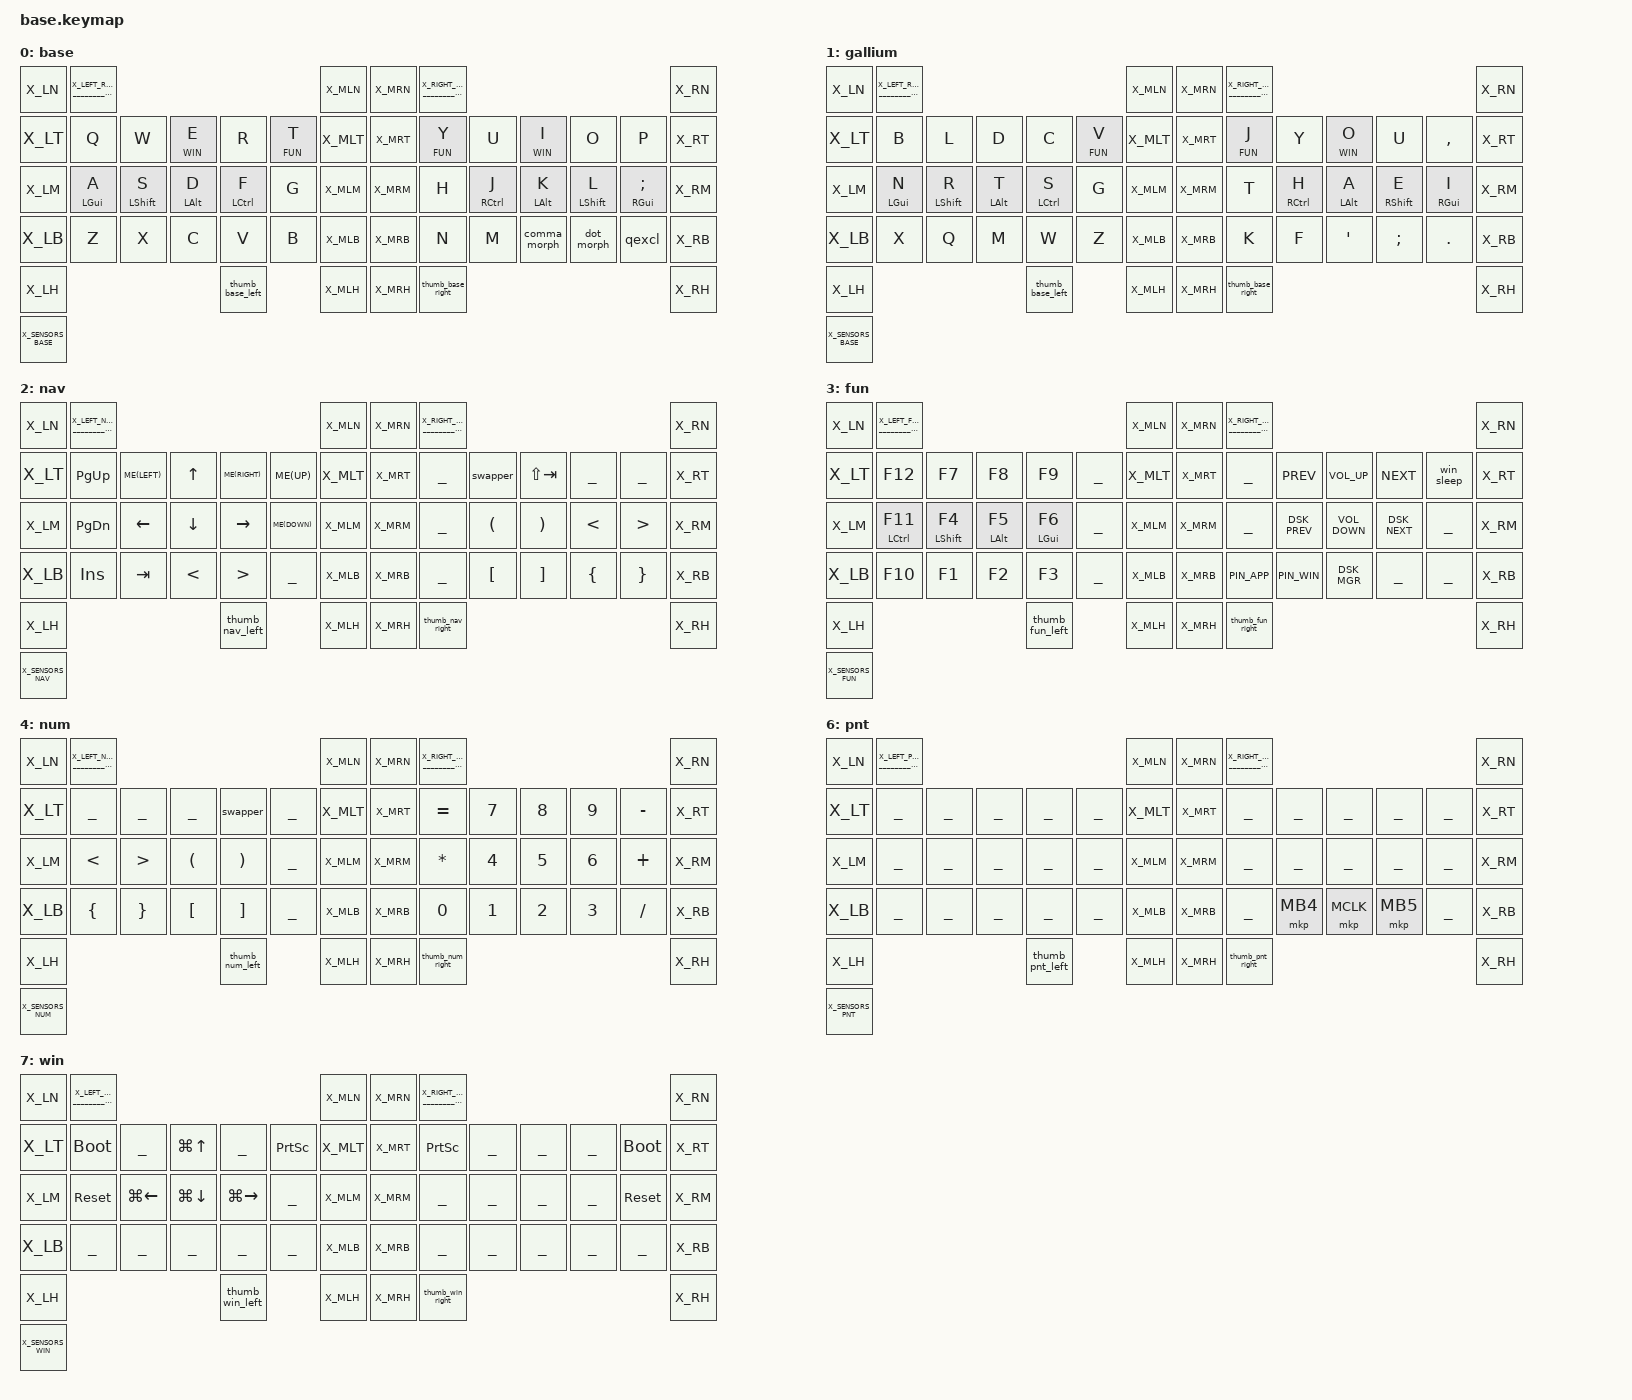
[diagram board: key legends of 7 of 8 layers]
#include <behaviors.dtsi>
#include <dt-bindings/zmk/keys.h>

#include "zmk-helpers/helper.h"

#include "../spacerock/aliases.h"
#include "../spacerock/extra_keys.h"
#include "../spacerock/layouts.h"

#include "../spacerock/hardware/hardware.dtsi"
#include "../spacerock/behaviors/behaviors.dtsi"
#include "../spacerock/behaviors/leader.dtsi"

#include "../spacerock/features/hrm.dtsi"
#include "../spacerock/features/mask_mods.dtsi"
#include "../spacerock/features/caps_word.dtsi"
#include "../spacerock/features/num_word.dtsi"
#include "../spacerock/features/smart_mouse.dtsi"
#include "../spacerock/features/swapper.dtsi"
#include "../spacerock/features/smart_shift.dtsi"
// #include "features/nav_word.dtsi"

#include "../spacerock/combos.dtsi"  // requires layer aliases

ZMK_CONDITIONAL_LAYER(cond_sys, NAV NUM, SYS)  // FUN + NUM --> SYSge

ZMK_LAYER(base,
    X_LN    ________________________X_LEFT_ROW_________________________________    X_MLN   X_MRN   ________________________X_RIGHT_ROW________________________________    X_RN
    X_LT    &kp Q         &kp W         &lt WIN E     &kp R         &lt FUN T      X_MLT   X_MRT   &lt FUN Y     &kp U         &lt WIN I     &kp O         &kp P          X_RT
    X_LM    &hml LGUI A   &hml LSHFT S  &hml LALT D   &hml LCTRL F  &kp G          X_MLM   X_MRM   &kp H         &hmr RCTRL J  &hmr LALT K   &hmr LSHFT L  &hmr RGUI SEMI X_RM
    X_LB    &kp Z         &kp X         &kp C         &kp V         &kp B          X_MLB   X_MRB   &kp N         &kp M         &comma_morph  &dot_morph    &qexcl         X_RB
    X_LH                                              thumb_base_left              X_MLH   X_MRH   thumb_base_right                                                       X_RH
    X_SENSORS_BASE
)

ZMK_LAYER(gallium,
    X_LN    ________________________X_LEFT_ROW_________________________________    X_MLN   X_MRN   ________________________X_RIGHT_ROW________________________________    X_RN
    X_LT    &kp B         &kp L         &kp D         &kp C         &lt FUN V      X_MLT   X_MRT   &lt FUN J     &kp Y         &lt WIN O     &kp U         &kp COMMA      X_RT
    X_LM    &hml LGUI N   &hml LSHFT R  &hml LALT T   &hml LCTRL S  &kp G          X_MLM   X_MRM   &kp T         &hmr RCTRL H  &hmr LALT A   &hmr RSHFT E  &hmr RGUI I    X_RM
    X_LB    &kp X         &kp Q         &kp M         &kp W         &kp Z          X_MLB   X_MRB   &kp K         &kp F         &kp APOS      &kp SEMI      &kp DOT        X_RB
    X_LH                                              thumb_base_left              X_MLH   X_MRH   thumb_base_right                                                       X_RH
    X_SENSORS_BASE
)

ZMK_LAYER(nav,
    X_LN    ________________________X_LEFT_NAV_________________________________    X_MLN   X_MRN   ________________________X_RIGHT_NAV________________________________    X_RN
    X_LT    &kp PG_UP     &kp ME(LEFT)  &kp UP        &kp ME(RIGHT) &kp ME(UP)     X_MLT   X_MRT   ___           &swapper      &kp LS(TAB)   ___           ___            X_RT
    X_LM    &kp PG_DN     &kp LEFT      &kp DOWN      &kp RIGHT     &kp ME(DOWN)   X_MLM   X_MRM   ___           &kp LPAR      &kp RPAR      &kp LT        &kp GT         X_RM
    X_LB    &kp INS       &kp TAB       &kp LT        &kp GT        ___            X_MLB   X_MRB   ___           &kp LBKT      &kp RBKT      &kp LBRC      &kp RBRC       X_RB
    X_LH                                              thumb_nav_left               X_MLH   X_MRH   thumb_nav_right                                                        X_RH
    X_SENSORS_NAV
)

ZMK_LAYER(fun,
    X_LN    ________________________X_LEFT_FUN_________________________________    X_MLN   X_MRN   ________________________X_RIGHT_FUN________________________________    X_RN
    X_LT    &kp F12       &kp F7        &kp F8        &kp F9        ___            X_MLT   X_MRT   ___           &kp C_PREV    &kp C_VOL_UP  &kp C_NEXT    &win_sleep     X_RT
    X_LM    &hml LCTRL F11 &hml LSHFT F4 &hml LALT F5 &hml LGUI F6  ___            X_MLM   X_MRM   ___           DSK_PREV      VOL_DOWN      DSK_NEXT      ___            X_RM
    X_LB    &kp F10       &kp F1        &kp F2        &kp F3        ___            X_MLB   X_MRB   PIN_APP       PIN_WIN       DSK_MGR       ___           ___            X_RB
    X_LH                                              thumb_fun_left               X_MLH   X_MRH   thumb_fun_right                                                        X_RH
    X_SENSORS_FUN
)

ZMK_LAYER(num,
    X_LN    ________________________X_LEFT_NUM_________________________________    X_MLN   X_MRN   ________________________X_RIGHT_NUM________________________________    X_RN
    X_LT    ___           ___           ___           &swapper      ___            X_MLT   X_MRT   &kp EQUAL     &kp N7        &kp N8        &kp N9        &kp MINUS      X_RT
    X_LM    &kp LT        &kp GT        &kp LPAR      &kp RPAR      ___            X_MLM   X_MRM   &kp ASTRK     &kp N4        &kp N5        &kp N6        &kp PLUS       X_RM
    X_LB    &kp LBRC      &kp RBRC      &kp LBKT      &kp RBKT      ___            X_MLB   X_MRB   &kp N0        &kp N1        &kp N2        &kp N3        &kp FSLH       X_RB
    X_LH                                              thumb_num_left               X_MLH   X_MRH   thumb_num_right                                                        X_RH
    X_SENSORS_NUM
)

ZMK_LAYER(sys,
    X_LN    ________________________X_LEFT_SYS_________________________________    X_MLN   X_MRN   ________________________X_RIGHT_SYS________________________________    X_RN
    X_LT    ____________________________BT_SEL_KEYS____________________________    X_MLT   X_MRT   ___           ___           ___           ___           ___            X_RT
    X_LM    ___           ___           ___           ___           &bootloader    X_MLM   X_MRM   &bootloader   ___           ___           ___           ___            X_RM
    X_LB    &soft_off     ___           ___           ___           &sys_reset     X_MLB   X_MRB   &sys_reset    ___           ___           ___           &soft_off      X_RB
    X_LH                                              thumb_sys_left               X_MLH   X_MRH   thumb_sys_right                                                        X_RH
    X_SENSORS_SYS
)

ZMK_LAYER(pnt,
    X_LN    ________________________X_LEFT_PNT_________________________________    X_MLN   X_MRN   ________________________X_RIGHT_PNT________________________________    X_RN
    X_LT    ___           ___           ___           ___           ___            X_MLT   X_MRT   ___           ___           ___           ___           ___            X_RT
    X_LM    ___           ___           ___           ___           ___            X_MLM   X_MRM   ___           ___           ___           ___           ___            X_RM
    X_LB    ___           ___           ___           ___           ___            X_MLB   X_MRB   ___           &mkp MB4      &mkp MCLK     &mkp MB5      ___            X_RB
    X_LH                                              thumb_pnt_left               X_MLH   X_MRH   thumb_pnt_right                                              X_RH
    X_SENSORS_PNT
)

ZMK_LAYER(win,
    X_LN    ________________________X_LEFT_WIN_________________________________    X_MLN   X_MRN   ________________________X_RIGHT_WIN________________________________    X_RN
    X_LT    &bootloader   ___           &kp LG(UP)    ___           &kp PSCRN      X_MLT   X_MRT   &kp PSCRN     ___           ___           ___           &bootloader    X_RT
    X_LM    &sys_reset    &kp LG(LEFT)  &kp LG(DOWN)  &kp LG(RIGHT) ___            X_MLM   X_MRM   ___           ___           ___           ___           &sys_reset     X_RM
    X_LB    ___           ___           ___           ___           ___            X_MLB   X_MRB   ___           ___           ___           ___           ___            X_RB
    X_LH                                              thumb_win_left               X_MLH   X_MRH   thumb_win_right                                                        X_RH
    X_SENSORS_WIN
)

// ZMK_LAYER(blank,
//     X_LN    ________________________X_LEFT_ROW_________________________________ X_MLN   X_MRN   ________________________X_RIGHT_ROW________________________________ X_RN
//     X_LT    ___           ___           ___           ___           ___         X_MLT   X_MRT   ___           ___           ___           ___           ___         X_RT
//     X_LM    ___           ___           ___           ___           ___         X_MLM   X_MRM   ___           ___           ___           ___           ___         X_RM
//     X_LB    ___           ___           ___           ___           ___         X_MLB   X_MRB   ___           ___           ___           ___           ___         X_RB
//     X_LH                                ___           ___           ___         X_MLH   X_MRH   ___           ___                                                   X_RH
//     X_SENSORS_WIN
// )

/* vim: set ft=  tw=174: */
